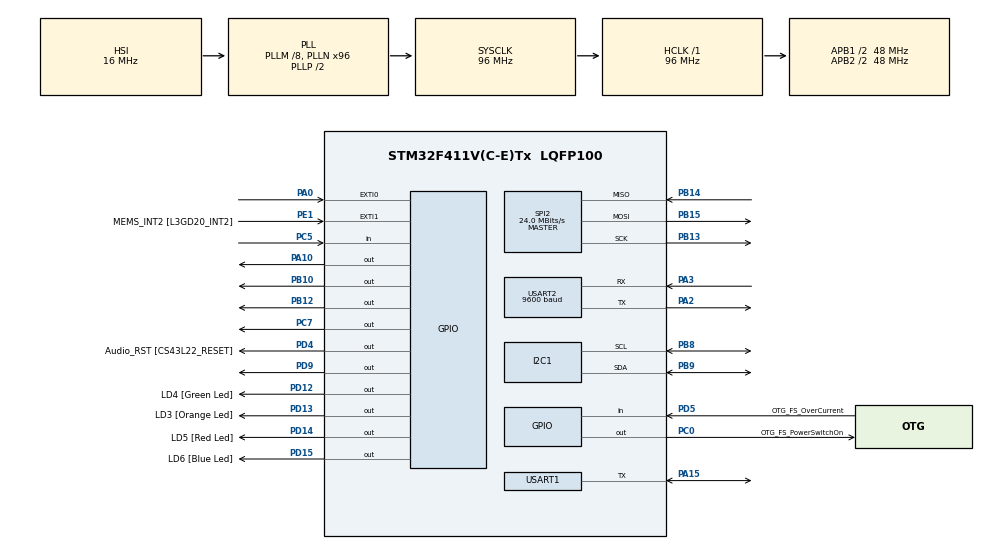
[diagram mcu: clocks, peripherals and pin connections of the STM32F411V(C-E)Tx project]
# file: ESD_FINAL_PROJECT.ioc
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Dma.Request0=USART1_RX
Dma.Request1=USART1_TX
Dma.Request2=SPI2_TX
Dma.Request3=SPI2_RX
Dma.SPI2_RX.3.Direction=DMA_PERIPH_TO_MEMORY
Dma.SPI2_RX.3.FIFOMode=DMA_FIFOMODE_DISABLE
Dma.SPI2_RX.3.Instance=DMA1_Stream3
Dma.SPI2_RX.3.MemDataAlignment=DMA_MDATAALIGN_BYTE
Dma.SPI2_RX.3.MemInc=DMA_MINC_ENABLE
Dma.SPI2_RX.3.Mode=DMA_NORMAL
Dma.SPI2_RX.3.PeriphDataAlignment=DMA_PDATAALIGN_BYTE
Dma.SPI2_RX.3.PeriphInc=DMA_PINC_DISABLE
Dma.SPI2_RX.3.Priority=DMA_PRIORITY_HIGH
Dma.SPI2_TX.2.Direction=DMA_MEMORY_TO_PERIPH
Dma.SPI2_TX.2.FIFOMode=DMA_FIFOMODE_DISABLE
Dma.SPI2_TX.2.Instance=DMA1_Stream4
Dma.SPI2_TX.2.MemDataAlignment=DMA_MDATAALIGN_BYTE
Dma.SPI2_TX.2.MemInc=DMA_MINC_ENABLE
Dma.SPI2_TX.2.Mode=DMA_NORMAL
Dma.SPI2_TX.2.PeriphDataAlignment=DMA_PDATAALIGN_BYTE
Dma.SPI2_TX.2.PeriphInc=DMA_PINC_DISABLE
Dma.SPI2_TX.2.Priority=DMA_PRIORITY_HIGH
Dma.USART1_RX.0.Direction=DMA_PERIPH_TO_MEMORY
Dma.USART1_RX.0.FIFOMode=DMA_FIFOMODE_DISABLE
Dma.USART1_RX.0.Instance=DMA2_Stream2
Dma.USART1_RX.0.MemDataAlignment=DMA_MDATAALIGN_BYTE
Dma.USART1_RX.0.MemInc=DMA_MINC_ENABLE
Dma.USART1_RX.0.Mode=DMA_NORMAL
Dma.USART1_RX.0.PeriphDataAlignment=DMA_PDATAALIGN_BYTE
Dma.USART1_RX.0.PeriphInc=DMA_PINC_DISABLE
Dma.USART1_RX.0.Priority=DMA_PRIORITY_LOW
Dma.USART1_TX.1.Direction=DMA_MEMORY_TO_PERIPH
Dma.USART1_TX.1.FIFOMode=DMA_FIFOMODE_DISABLE
Dma.USART1_TX.1.Instance=DMA2_Stream7
Dma.USART1_TX.1.MemDataAlignment=DMA_MDATAALIGN_BYTE
Dma.USART1_TX.1.MemInc=DMA_MINC_ENABLE
Dma.USART1_TX.1.Mode=DMA_NORMAL
Dma.USART1_TX.1.PeriphDataAlignment=DMA_PDATAALIGN_BYTE
Dma.USART1_TX.1.PeriphInc=DMA_PINC_DISABLE
Dma.USART1_TX.1.Priority=DMA_PRIORITY_LOW
FATFS._MAX_SS=4096
FATFS._USE_LFN=1
I2C1.I2C_Mode=I2C_Standard
Mcu.Family=STM32F4
Mcu.Name=STM32F411V(C-E)Tx
Mcu.Package=LQFP100
NVIC.DMA1_Stream3_IRQn=true\:0\:0\:false\:false\:true\:false\:true\:true
NVIC.DMA1_Stream4_IRQn=true\:0\:0\:false\:false\:true\:false\:true\:true
NVIC.DMA2_Stream2_IRQn=true\:0\:0\:false\:false\:true\:false\:true\:true
NVIC.DMA2_Stream7_IRQn=true\:0\:0\:false\:false\:true\:false\:true\:true
NVIC.PriorityGroup=NVIC_PRIORITYGROUP_0
NVIC.SPI2_IRQn=true\:0\:0\:false\:false\:true\:true\:true\:true
NVIC.USART1_IRQn=true\:0\:0\:false\:false\:true\:true\:true\:true
PA0-WKUP.GPIO_ModeDefaultEXTI=GPIO_MODE_EVT_RISING
PA0-WKUP.Signal=GPXTI0
PA10.Signal=GPIO_Output
PA11.GPIO_Label=OTG_FS_DM
PA11.Signal=USB_OTG_FS_DM
PA12.GPIO_Label=OTG_FS_DP
PA12.Signal=USB_OTG_FS_DP
PA13.GPIO_Label=SWDIO
PA13.Signal=SYS_JTMS-SWDIO
PA14.GPIO_Label=SWCLK
PA14.Signal=SYS_JTCK-SWCLK
PA15.Mode=Half_duplex(single_wire_mode)
PA15.Signal=USART1_TX
PA2.Mode=Asynchronous
PA2.Signal=USART2_TX
PA3.Mode=Asynchronous
PA3.Signal=USART2_RX
PA9.GPIO_Label=VBUS_FS
PA9.Signal=USB_OTG_FS_VBUS
PB10.Signal=GPIO_Output
PB12.Signal=GPIO_Output
PB13.Mode=Full_Duplex_Master
PB13.Signal=SPI2_SCK
PB14.Mode=Full_Duplex_Master
PB14.Signal=SPI2_MISO
PB15.Mode=Full_Duplex_Master
PB15.Signal=SPI2_MOSI
PB3.GPIO_Label=SWO
PB3.Signal=SYS_JTDO-SWO
PB8.Mode=I2C
PB8.Signal=I2C1_SCL
PB9.Mode=I2C
PB9.Signal=I2C1_SDA
PC0.GPIO_Label=OTG_FS_PowerSwitchOn
PC0.PinState=GPIO_PIN_SET
PC0.Signal=GPIO_Output
PC14-OSC32_IN.GPIO_Label=PC14-OSC32_IN
PC14-OSC32_IN.Signal=RCC_OSC32_IN
PC15-OSC32_OUT.GPIO_Label=PC15-OSC32_OUT
PC15-OSC32_OUT.Signal=RCC_OSC32_OUT
PC3.GPIO_Label=PDM_OUT [MP45DT02_DOUT]
PC3.Signal=I2S2_SD
PC5.Signal=GPIO_Input
PC7.Signal=GPIO_Output
PD12.GPIO_Label=LD4 [Green Led]
PD12.GPIO_PuPd=GPIO_NOPULL
PD12.GPIO_Speed=GPIO_SPEED_FREQ_LOW
PD12.Signal=GPIO_Output
PD13.GPIO_Label=LD3 [Orange Led]
PD13.GPIO_PuPd=GPIO_NOPULL
PD13.GPIO_Speed=GPIO_SPEED_FREQ_LOW
PD13.Signal=GPIO_Output
PD14.GPIO_Label=LD5 [Red Led]
PD14.GPIO_PuPd=GPIO_NOPULL
PD14.GPIO_Speed=GPIO_SPEED_FREQ_LOW
PD14.Signal=GPIO_Output
PD15.GPIO_Label=LD6 [Blue Led]
PD15.GPIO_PuPd=GPIO_NOPULL
PD15.GPIO_Speed=GPIO_SPEED_FREQ_LOW
PD15.Signal=GPIO_Output
PD4.GPIO_Label=Audio_RST [CS43L22_RESET]
PD4.Signal=GPIO_Output
PD5.GPIO_Label=OTG_FS_OverCurrent
PD5.Signal=GPIO_Input
PD9.Signal=GPIO_Output
PE1.GPIO_Label=MEMS_INT2 [L3GD20_INT2]
PE1.GPIO_ModeDefaultEXTI=GPIO_MODE_EVT_RISING
PE1.Signal=GPXTI1
PH0\ -\ OSC_IN.GPIO_Label=PH0-OSC_IN
PH0\ -\ OSC_IN.Signal=RCC_OSC_IN
PH1\ -\ OSC_OUT.GPIO_Label=PH1-OSC_OUT
PH1\ -\ OSC_OUT.Signal=RCC_OSC_OUT
ProjectManager.HeapSize=0x200
ProjectManager.StackSize=0x400
ProjectManager.TargetToolchain=STM32CubeIDE
RCC.48MHZClocksFreq_Value=24000000
RCC.AHBFreq_Value=96000000
RCC.APB1CLKDivider=RCC_HCLK_DIV2
RCC.APB1Freq_Value=48000000
RCC.APB1TimFreq_Value=96000000
RCC.APB2CLKDivider=RCC_HCLK_DIV2
RCC.APB2Freq_Value=48000000
RCC.APB2TimFreq_Value=96000000
RCC.CortexFreq_Value=96000000
RCC.HCLKFreq_Value=96000000
RCC.HSE_VALUE=8000000
RCC.HSI_VALUE=16000000
RCC.LSE_VALUE=32768
RCC.PLLI2SM=5
RCC.PLLI2SN=200
RCC.PLLM=8
RCC.PLLN=96
RCC.PLLQ=8
RCC.SYSCLKFreq_VALUE=96000000
RCC.SYSCLKSource=RCC_SYSCLKSOURCE_PLLCLK
RCC.VCOOutputFreq_Value=192000000
SPI2.BaudRatePrescaler=SPI_BAUDRATEPRESCALER_2
SPI2.CalculateBaudRate=24.0 MBits/s
SPI2.Direction=SPI_DIRECTION_2LINES
SPI2.Mode=SPI_MODE_MASTER
SPI2.VirtualType=VM_MASTER
USART1.VirtualMode=VM_ASYNC
USART2.BaudRate=9600
USART2.VirtualMode=VM_ASYNC
VP_FATFS_VS_Generic.Mode=User_defined
board=STM32F411E-DISCO

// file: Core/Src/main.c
/* USER CODE BEGIN Header */
/**
  ******************************************************************************
  * @file           : main.c
  * @brief          : Main program body
  ******************************************************************************
  * @attention
  *
  * Copyright (c) 2024 STMicroelectronics.
  * All rights reserved.
  *
  * This software is licensed under terms that can be found in the LICENSE file
  * in the root directory of this software component.
  * If no LICENSE file comes with this software, it is provided AS-IS.
  *
  ******************************************************************************
  */
/* USER CODE END Header */
#include "main.h"
#include "fatfs.h"
#include "accelerometer.h"
#include "integration.h"
#include "IRSensor.h"
#include "uart_init.h"
#include "fonts.h"
#include "lcd.h"
#include "lcd_functions.h"

I2C_HandleTypeDef hi2c1;

SPI_HandleTypeDef hspi2;
DMA_HandleTypeDef hdma_spi2_tx;
DMA_HandleTypeDef hdma_spi2_rx;

UART_HandleTypeDef huart1;
UART_HandleTypeDef huart2;
DMA_HandleTypeDef hdma_usart1_rx;
DMA_HandleTypeDef hdma_usart1_tx;

void SystemClock_Config(void);
static void MX_GPIO_Init(void);
static void MX_DMA_Init(void);
static void MX_USART1_UART_Init(void);
static void MX_SPI2_Init(void);
static void MX_I2C1_Init(void);
static void MX_USART2_UART_Init(void);

int main(void)
{

  /* MCU Configuration--------------------------------------------------------*/

  /* Reset of all peripherals, Initializes the Flash interface and the Systick. */
  HAL_Init();

  /* Configure the system clock */
  SystemClock_Config();

  /* Initialize all configured peripherals */
  MX_GPIO_Init();
  MX_DMA_Init();
  MX_USART1_UART_Init();
  MX_SPI2_Init();
  MX_I2C1_Init();
  MX_FATFS_Init();
  MX_USART2_UART_Init();
  init_game();
  /* USER CODE BEGIN 2 */

  //DisplayBitmapFromSD("FREQUENCY.bmp");
  // Draw a single character
  // Draw 'A' with double size

  /* USER CODE END 2 */

  /* Infinite loop */
  while (1)
  {
	  game_state_machine();
  }
}

void SystemClock_Config(void)
{
  RCC_OscInitTypeDef RCC_OscInitStruct = {0};
  RCC_ClkInitTypeDef RCC_ClkInitStruct = {0};

  /** Configure the main internal regulator output voltage
  */
  __HAL_RCC_PWR_CLK_ENABLE();
  __HAL_PWR_VOLTAGESCALING_CONFIG(PWR_REGULATOR_VOLTAGE_SCALE1);

  /** Initializes the RCC Oscillators according to the specified parameters
  * in the RCC_OscInitTypeDef structure.
  */
  RCC_OscInitStruct.OscillatorType = RCC_OSCILLATORTYPE_HSI;
  RCC_OscInitStruct.HSIState = RCC_HSI_ON;
  RCC_OscInitStruct.HSICalibrationValue = RCC_HSICALIBRATION_DEFAULT;
  RCC_OscInitStruct.PLL.PLLState = RCC_PLL_ON;
  RCC_OscInitStruct.PLL.PLLSource = RCC_PLLSOURCE_HSI;
  RCC_OscInitStruct.PLL.PLLM = 8;
  RCC_OscInitStruct.PLL.PLLN = 96;
  RCC_OscInitStruct.PLL.PLLP = RCC_PLLP_DIV2;
  RCC_OscInitStruct.PLL.PLLQ = 8;
  if (HAL_RCC_OscConfig(&RCC_OscInitStruct) != HAL_OK)
  {
    Error_Handler();
  }

  /** Initializes the CPU, AHB and APB buses clocks
  */
  RCC_ClkInitStruct.ClockType = RCC_CLOCKTYPE_HCLK|RCC_CLOCKTYPE_SYSCLK
                              |RCC_CLOCKTYPE_PCLK1|RCC_CLOCKTYPE_PCLK2;
  RCC_ClkInitStruct.SYSCLKSource = RCC_SYSCLKSOURCE_PLLCLK;
  RCC_ClkInitStruct.AHBCLKDivider = RCC_SYSCLK_DIV1;
  RCC_ClkInitStruct.APB1CLKDivider = RCC_HCLK_DIV2;
  RCC_ClkInitStruct.APB2CLKDivider = RCC_HCLK_DIV2;

  if (HAL_RCC_ClockConfig(&RCC_ClkInitStruct, FLASH_LATENCY_3) != HAL_OK)
  {
    Error_Handler();
  }
}

static void MX_I2C1_Init(void)
{

  hi2c1.Instance = I2C1;
  hi2c1.Init.ClockSpeed = 100000;
  hi2c1.Init.DutyCycle = I2C_DUTYCYCLE_2;
  hi2c1.Init.OwnAddress1 = 0;
  hi2c1.Init.AddressingMode = I2C_ADDRESSINGMODE_7BIT;
  hi2c1.Init.DualAddressMode = I2C_DUALADDRESS_DISABLE;
  hi2c1.Init.OwnAddress2 = 0;
  hi2c1.Init.GeneralCallMode = I2C_GENERALCALL_DISABLE;
  hi2c1.Init.NoStretchMode = I2C_NOSTRETCH_DISABLE;
  if (HAL_I2C_Init(&hi2c1) != HAL_OK)
  {
    Error_Handler();
  }

}

static void MX_SPI2_Init(void)
{

  /* SPI2 parameter configuration*/
  hspi2.Instance = SPI2;
  hspi2.Init.Mode = SPI_MODE_MASTER;
  hspi2.Init.Direction = SPI_DIRECTION_2LINES;
  hspi2.Init.DataSize = SPI_DATASIZE_8BIT;
  hspi2.Init.CLKPolarity = SPI_POLARITY_LOW;
  hspi2.Init.CLKPhase = SPI_PHASE_1EDGE;
  hspi2.Init.NSS = SPI_NSS_SOFT;
  hspi2.Init.BaudRatePrescaler = SPI_BAUDRATEPRESCALER_2;
  hspi2.Init.FirstBit = SPI_FIRSTBIT_MSB;
  hspi2.Init.TIMode = SPI_TIMODE_DISABLE;
  hspi2.Init.CRCCalculation = SPI_CRCCALCULATION_DISABLE;
  hspi2.Init.CRCPolynomial = 10;
  if (HAL_SPI_Init(&hspi2) != HAL_OK)
  {
    Error_Handler();
  }

}

static void MX_USART1_UART_Init(void)
{

  huart1.Instance = USART1;
  huart1.Init.BaudRate = 115200;
  huart1.Init.WordLength = UART_WORDLENGTH_8B;
  huart1.Init.StopBits = UART_STOPBITS_1;
  huart1.Init.Parity = UART_PARITY_NONE;
  huart1.Init.Mode = UART_MODE_TX_RX;
  huart1.Init.HwFlowCtl = UART_HWCONTROL_NONE;
  huart1.Init.OverSampling = UART_OVERSAMPLING_16;
  if (HAL_HalfDuplex_Init(&huart1) != HAL_OK)
  {
    Error_Handler();
  }

}

static void MX_USART2_UART_Init(void)
{

  huart2.Instance = USART2;
  huart2.Init.BaudRate = 9600;
  huart2.Init.WordLength = UART_WORDLENGTH_8B;
  huart2.Init.StopBits = UART_STOPBITS_1;
  huart2.Init.Parity = UART_PARITY_NONE;
  huart2.Init.Mode = UART_MODE_TX_RX;
  huart2.Init.HwFlowCtl = UART_HWCONTROL_NONE;
  huart2.Init.OverSampling = UART_OVERSAMPLING_16;
  if (HAL_UART_Init(&huart2) != HAL_OK)
  {
    Error_Handler();
  }

}

static void MX_DMA_Init(void)
{

  /* DMA controller clock enable */
  __HAL_RCC_DMA2_CLK_ENABLE();
  __HAL_RCC_DMA1_CLK_ENABLE();

  /* DMA interrupt init */
  /* DMA1_Stream3_IRQn interrupt configuration */
  HAL_NVIC_SetPriority(DMA1_Stream3_IRQn, 0, 0);
  HAL_NVIC_EnableIRQ(DMA1_Stream3_IRQn);
  /* DMA1_Stream4_IRQn interrupt configuration */
  HAL_NVIC_SetPriority(DMA1_Stream4_IRQn, 0, 0);
  HAL_NVIC_EnableIRQ(DMA1_Stream4_IRQn);
  /* DMA2_Stream2_IRQn interrupt configuration */
  HAL_NVIC_SetPriority(DMA2_Stream2_IRQn, 0, 0);
  HAL_NVIC_EnableIRQ(DMA2_Stream2_IRQn);
  /* DMA2_Stream7_IRQn interrupt configuration */
  HAL_NVIC_SetPriority(DMA2_Stream7_IRQn, 0, 0);
  HAL_NVIC_EnableIRQ(DMA2_Stream7_IRQn);

}

static void MX_GPIO_Init(void)
{
  GPIO_InitTypeDef GPIO_InitStruct = {0};

  /* GPIO Ports Clock Enable */
  __HAL_RCC_GPIOC_CLK_ENABLE();
  __HAL_RCC_GPIOH_CLK_ENABLE();
  __HAL_RCC_GPIOA_CLK_ENABLE();
  __HAL_RCC_GPIOB_CLK_ENABLE();
  __HAL_RCC_GPIOD_CLK_ENABLE();
  __HAL_RCC_GPIOE_CLK_ENABLE();

  /*Configure GPIO pin Output Level */
  HAL_GPIO_WritePin(OTG_FS_PowerSwitchOn_GPIO_Port, OTG_FS_PowerSwitchOn_Pin, GPIO_PIN_SET);

  /*Configure GPIO pin Output Level */
  HAL_GPIO_WritePin(GPIOB, GPIO_PIN_10|GPIO_PIN_12, GPIO_PIN_RESET);

  /*Configure GPIO pin Output Level */
  HAL_GPIO_WritePin(GPIOD, GPIO_PIN_9|LD4_Pin|LD3_Pin|LD5_Pin
                          |LD6_Pin|Audio_RST_Pin, GPIO_PIN_RESET);

  /*Configure GPIO pin Output Level */
  HAL_GPIO_WritePin(GPIOC, GPIO_PIN_7, GPIO_PIN_RESET);

  /*Configure GPIO pin Output Level */
  HAL_GPIO_WritePin(GPIOA, GPIO_PIN_10, GPIO_PIN_RESET);

  /*Configure GPIO pins : OTG_FS_PowerSwitchOn_Pin PC7 */
  GPIO_InitStruct.Pin = OTG_FS_PowerSwitchOn_Pin|GPIO_PIN_7;
  GPIO_InitStruct.Mode = GPIO_MODE_OUTPUT_PP;
  GPIO_InitStruct.Pull = GPIO_NOPULL;
  GPIO_InitStruct.Speed = GPIO_SPEED_FREQ_LOW;
  HAL_GPIO_Init(GPIOC, &GPIO_InitStruct);

  /*Configure GPIO pin : PDM_OUT_Pin */
  GPIO_InitStruct.Pin = PDM_OUT_Pin;
  GPIO_InitStruct.Mode = GPIO_MODE_AF_PP;
  GPIO_InitStruct.Pull = GPIO_NOPULL;
  GPIO_InitStruct.Speed = GPIO_SPEED_FREQ_LOW;
  GPIO_InitStruct.Alternate = GPIO_AF5_SPI2;
  HAL_GPIO_Init(PDM_OUT_GPIO_Port, &GPIO_InitStruct);

  /*Configure GPIO pin : PA0 */
  GPIO_InitStruct.Pin = GPIO_PIN_0;
  GPIO_InitStruct.Mode = GPIO_MODE_EVT_RISING;
  GPIO_InitStruct.Pull = GPIO_NOPULL;
  HAL_GPIO_Init(GPIOA, &GPIO_InitStruct);

  /*Configure GPIO pin : PC5 */
  GPIO_InitStruct.Pin = GPIO_PIN_5;
  GPIO_InitStruct.Mode = GPIO_MODE_INPUT;
  GPIO_InitStruct.Pull = GPIO_NOPULL;
  HAL_GPIO_Init(GPIOC, &GPIO_InitStruct);

  /*Configure GPIO pins : PB10 PB12 */
  GPIO_InitStruct.Pin = GPIO_PIN_10|GPIO_PIN_12;
  GPIO_InitStruct.Mode = GPIO_MODE_OUTPUT_PP;
  GPIO_InitStruct.Pull = GPIO_NOPULL;
  GPIO_InitStruct.Speed = GPIO_SPEED_FREQ_LOW;
  HAL_GPIO_Init(GPIOB, &GPIO_InitStruct);

  /*Configure GPIO pins : PD9 LD4_Pin LD3_Pin LD5_Pin
                           LD6_Pin Audio_RST_Pin */
  GPIO_InitStruct.Pin = GPIO_PIN_9|LD4_Pin|LD3_Pin|LD5_Pin
                          |LD6_Pin|Audio_RST_Pin;
  GPIO_InitStruct.Mode = GPIO_MODE_OUTPUT_PP;
  GPIO_InitStruct.Pull = GPIO_NOPULL;
  GPIO_InitStruct.Speed = GPIO_SPEED_FREQ_LOW;
  HAL_GPIO_Init(GPIOD, &GPIO_InitStruct);

  /*Configure GPIO pin : VBUS_FS_Pin */
  GPIO_InitStruct.Pin = VBUS_FS_Pin;
  GPIO_InitStruct.Mode = GPIO_MODE_INPUT;
  GPIO_InitStruct.Pull = GPIO_NOPULL;
  HAL_GPIO_Init(VBUS_FS_GPIO_Port, &GPIO_InitStruct);

  /*Configure GPIO pin : PA10 */
  GPIO_InitStruct.Pin = GPIO_PIN_10;
  GPIO_InitStruct.Mode = GPIO_MODE_OUTPUT_PP;
  GPIO_InitStruct.Pull = GPIO_NOPULL;
  GPIO_InitStruct.Speed = GPIO_SPEED_FREQ_LOW;
  HAL_GPIO_Init(GPIOA, &GPIO_InitStruct);

  /*Configure GPIO pins : OTG_FS_DM_Pin OTG_FS_DP_Pin */
  GPIO_InitStruct.Pin = OTG_FS_DM_Pin|OTG_FS_DP_Pin;
  GPIO_InitStruct.Mode = GPIO_MODE_AF_PP;
  GPIO_InitStruct.Pull = GPIO_NOPULL;
  GPIO_InitStruct.Speed = GPIO_SPEED_FREQ_VERY_HIGH;
  GPIO_InitStruct.Alternate = GPIO_AF10_OTG_FS;
  HAL_GPIO_Init(GPIOA, &GPIO_InitStruct);

  /*Configure GPIO pin : OTG_FS_OverCurrent_Pin */
  GPIO_InitStruct.Pin = OTG_FS_OverCurrent_Pin;
  GPIO_InitStruct.Mode = GPIO_MODE_INPUT;
  GPIO_InitStruct.Pull = GPIO_NOPULL;
  HAL_GPIO_Init(OTG_FS_OverCurrent_GPIO_Port, &GPIO_InitStruct);

  /*Configure GPIO pin : MEMS_INT2_Pin */
  GPIO_InitStruct.Pin = MEMS_INT2_Pin;
  GPIO_InitStruct.Mode = GPIO_MODE_EVT_RISING;
  GPIO_InitStruct.Pull = GPIO_NOPULL;
  HAL_GPIO_Init(MEMS_INT2_GPIO_Port, &GPIO_InitStruct);

}

/* USER CODE BEGIN 4 */
#ifdef __GNUC__
  /* With GCC, small printf (option LD Linker->Libraries->Small printf
     set to 'Yes') calls __io_putchar() */
int __io_putchar(int ch)
#else
int fputc(int ch, FILE *f)
#endif /* __GNUC__ */
{
  /* Place your implementation of fputc here */
  /* e.g. write a character to the UART3 and Loop until the end of transmission */
  HAL_UART_Transmit(&huart2, (uint8_t *)&ch, 1, HAL_MAX_DELAY);
  return ch;
}
/* USER CODE BEGIN 4 */
/* USER CODE BEGIN 4 */
/* USER CODE END 4 */

void Error_Handler(void)
{
  __disable_irq();
  while (1)
  {
  }
}
